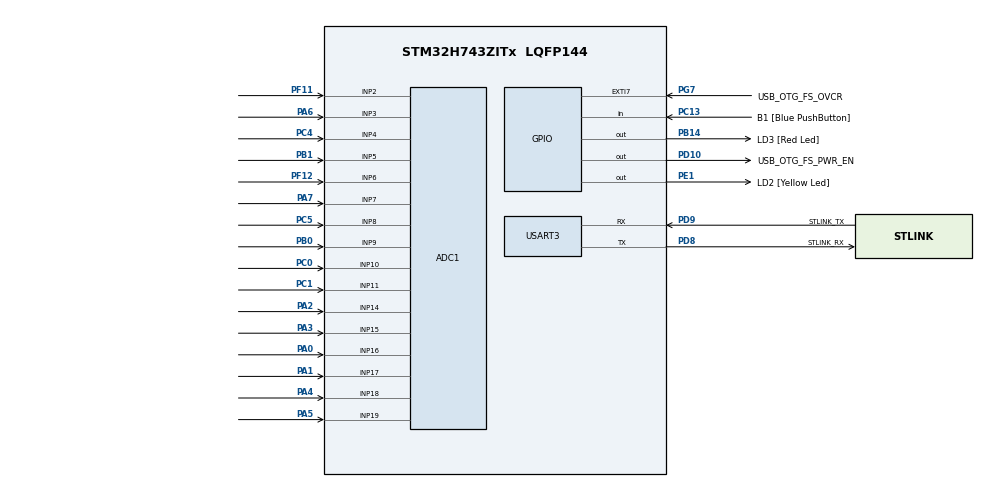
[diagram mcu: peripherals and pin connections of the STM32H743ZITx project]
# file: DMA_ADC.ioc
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ADC1.Channel-0\#ChannelRegularConversion=ADC_CHANNEL_2
ADC1.Channel-1\#ChannelRegularConversion=ADC_CHANNEL_3
ADC1.Channel-10\#ChannelRegularConversion=ADC_CHANNEL_14
ADC1.Channel-11\#ChannelRegularConversion=ADC_CHANNEL_15
ADC1.Channel-12\#ChannelRegularConversion=ADC_CHANNEL_16
ADC1.Channel-13\#ChannelRegularConversion=ADC_CHANNEL_17
ADC1.Channel-14\#ChannelRegularConversion=ADC_CHANNEL_18
ADC1.Channel-15\#ChannelRegularConversion=ADC_CHANNEL_19
ADC1.Channel-2\#ChannelRegularConversion=ADC_CHANNEL_4
ADC1.Channel-3\#ChannelRegularConversion=ADC_CHANNEL_5
ADC1.Channel-4\#ChannelRegularConversion=ADC_CHANNEL_6
ADC1.Channel-5\#ChannelRegularConversion=ADC_CHANNEL_7
ADC1.Channel-6\#ChannelRegularConversion=ADC_CHANNEL_8
ADC1.Channel-7\#ChannelRegularConversion=ADC_CHANNEL_9
ADC1.Channel-8\#ChannelRegularConversion=ADC_CHANNEL_10
ADC1.Channel-9\#ChannelRegularConversion=ADC_CHANNEL_11
ADC1.ClockPrescaler=ADC_CLOCK_ASYNC_DIV2
ADC1.ContinuousConvMode=ENABLE
ADC1.ConversionDataManagement=ADC_CONVERSIONDATA_DMA_CIRCULAR
ADC1.NbrOfConversion=16
ADC1.NbrOfConversionFlag=1
ADC1.OffsetNumber-0\#ChannelRegularConversion=ADC_OFFSET_NONE
ADC1.OffsetNumber-1\#ChannelRegularConversion=ADC_OFFSET_NONE
ADC1.OffsetNumber-10\#ChannelRegularConversion=ADC_OFFSET_NONE
ADC1.OffsetNumber-11\#ChannelRegularConversion=ADC_OFFSET_NONE
ADC1.OffsetNumber-12\#ChannelRegularConversion=ADC_OFFSET_NONE
ADC1.OffsetNumber-13\#ChannelRegularConversion=ADC_OFFSET_NONE
ADC1.OffsetNumber-14\#ChannelRegularConversion=ADC_OFFSET_NONE
ADC1.OffsetNumber-15\#ChannelRegularConversion=ADC_OFFSET_NONE
ADC1.OffsetNumber-2\#ChannelRegularConversion=ADC_OFFSET_NONE
ADC1.OffsetNumber-3\#ChannelRegularConversion=ADC_OFFSET_NONE
ADC1.OffsetNumber-4\#ChannelRegularConversion=ADC_OFFSET_NONE
ADC1.OffsetNumber-5\#ChannelRegularConversion=ADC_OFFSET_NONE
ADC1.OffsetNumber-6\#ChannelRegularConversion=ADC_OFFSET_NONE
ADC1.OffsetNumber-7\#ChannelRegularConversion=ADC_OFFSET_NONE
ADC1.OffsetNumber-8\#ChannelRegularConversion=ADC_OFFSET_NONE
ADC1.OffsetNumber-9\#ChannelRegularConversion=ADC_OFFSET_NONE
ADC1.OffsetSignedSaturation-0\#ChannelRegularConversion=DISABLE
ADC1.OffsetSignedSaturation-1\#ChannelRegularConversion=DISABLE
ADC1.OffsetSignedSaturation-10\#ChannelRegularConversion=DISABLE
ADC1.OffsetSignedSaturation-11\#ChannelRegularConversion=DISABLE
ADC1.OffsetSignedSaturation-12\#ChannelRegularConversion=DISABLE
ADC1.OffsetSignedSaturation-13\#ChannelRegularConversion=DISABLE
ADC1.OffsetSignedSaturation-14\#ChannelRegularConversion=DISABLE
ADC1.OffsetSignedSaturation-15\#ChannelRegularConversion=DISABLE
ADC1.OffsetSignedSaturation-2\#ChannelRegularConversion=DISABLE
ADC1.OffsetSignedSaturation-3\#ChannelRegularConversion=DISABLE
ADC1.OffsetSignedSaturation-4\#ChannelRegularConversion=DISABLE
ADC1.OffsetSignedSaturation-5\#ChannelRegularConversion=DISABLE
ADC1.OffsetSignedSaturation-6\#ChannelRegularConversion=DISABLE
ADC1.OffsetSignedSaturation-7\#ChannelRegularConversion=DISABLE
ADC1.OffsetSignedSaturation-8\#ChannelRegularConversion=DISABLE
ADC1.OffsetSignedSaturation-9\#ChannelRegularConversion=DISABLE
ADC1.Overrun=ADC_OVR_DATA_OVERWRITTEN
ADC1.Rank-0\#ChannelRegularConversion=1
ADC1.Rank-1\#ChannelRegularConversion=2
ADC1.Rank-10\#ChannelRegularConversion=11
ADC1.Rank-11\#ChannelRegularConversion=12
ADC1.Rank-12\#ChannelRegularConversion=13
ADC1.Rank-13\#ChannelRegularConversion=14
ADC1.Rank-14\#ChannelRegularConversion=15
ADC1.Rank-15\#ChannelRegularConversion=16
ADC1.Rank-2\#ChannelRegularConversion=3
ADC1.Rank-3\#ChannelRegularConversion=4
ADC1.Rank-4\#ChannelRegularConversion=5
ADC1.Rank-5\#ChannelRegularConversion=6
ADC1.Rank-6\#ChannelRegularConversion=7
ADC1.Rank-7\#ChannelRegularConversion=8
ADC1.Rank-8\#ChannelRegularConversion=9
ADC1.Rank-9\#ChannelRegularConversion=10
ADC1.SamplingTime-0\#ChannelRegularConversion=ADC_SAMPLETIME_1CYCLE_5
ADC1.SamplingTime-1\#ChannelRegularConversion=ADC_SAMPLETIME_1CYCLE_5
ADC1.SamplingTime-10\#ChannelRegularConversion=ADC_SAMPLETIME_1CYCLE_5
ADC1.SamplingTime-11\#ChannelRegularConversion=ADC_SAMPLETIME_1CYCLE_5
ADC1.SamplingTime-12\#ChannelRegularConversion=ADC_SAMPLETIME_1CYCLE_5
ADC1.SamplingTime-13\#ChannelRegularConversion=ADC_SAMPLETIME_1CYCLE_5
ADC1.SamplingTime-14\#ChannelRegularConversion=ADC_SAMPLETIME_1CYCLE_5
ADC1.SamplingTime-15\#ChannelRegularConversion=ADC_SAMPLETIME_1CYCLE_5
ADC1.SamplingTime-2\#ChannelRegularConversion=ADC_SAMPLETIME_1CYCLE_5
ADC1.SamplingTime-3\#ChannelRegularConversion=ADC_SAMPLETIME_1CYCLE_5
ADC1.SamplingTime-4\#ChannelRegularConversion=ADC_SAMPLETIME_1CYCLE_5
ADC1.SamplingTime-5\#ChannelRegularConversion=ADC_SAMPLETIME_1CYCLE_5
ADC1.SamplingTime-6\#ChannelRegularConversion=ADC_SAMPLETIME_1CYCLE_5
ADC1.SamplingTime-7\#ChannelRegularConversion=ADC_SAMPLETIME_1CYCLE_5
ADC1.SamplingTime-8\#ChannelRegularConversion=ADC_SAMPLETIME_1CYCLE_5
ADC1.SamplingTime-9\#ChannelRegularConversion=ADC_SAMPLETIME_1CYCLE_5
ADC1.master=1
CORTEX_M7.CPU_DCache=Disabled
Dma.ADC1.0.Direction=DMA_PERIPH_TO_MEMORY
Dma.ADC1.0.EventEnable=DISABLE
Dma.ADC1.0.FIFOMode=DMA_FIFOMODE_DISABLE
Dma.ADC1.0.Instance=DMA1_Stream0
Dma.ADC1.0.MemDataAlignment=DMA_MDATAALIGN_HALFWORD
Dma.ADC1.0.MemInc=DMA_MINC_ENABLE
Dma.ADC1.0.Mode=DMA_CIRCULAR
Dma.ADC1.0.PeriphDataAlignment=DMA_PDATAALIGN_HALFWORD
Dma.ADC1.0.PeriphInc=DMA_PINC_DISABLE
Dma.ADC1.0.Polarity=HAL_DMAMUX_REQ_GEN_RISING
Dma.ADC1.0.Priority=DMA_PRIORITY_HIGH
Dma.ADC1.0.RequestNumber=1
Dma.ADC1.0.SignalID=NONE
Dma.ADC1.0.SyncEnable=DISABLE
Dma.ADC1.0.SyncPolarity=HAL_DMAMUX_SYNC_NO_EVENT
Dma.ADC1.0.SyncRequestNumber=1
Dma.ADC1.0.SyncSignalID=NONE
Dma.Request0=ADC1
Mcu.Family=STM32H7
Mcu.Name=STM32H743ZITx
Mcu.Package=LQFP144
NVIC.DMA1_Stream0_IRQn=true\:0\:0\:false\:false\:true\:false\:true\:true
NVIC.PriorityGroup=NVIC_PRIORITYGROUP_4
NVIC.USART3_IRQn=true\:0\:0\:false\:false\:true\:true\:true\:true
PA0.Mode=IN16-Single-Ended
PA0.Signal=ADC1_INP16
PA1.Signal=SharedAnalog_PA1
PA11.Signal=USB_OTG_FS_DM
PA12.Signal=USB_OTG_FS_DP
PA13\ (JTMS/SWDIO).GPIO_Label=JTMS
PA13\ (JTMS/SWDIO).Signal=DEBUG_JTMS-SWDIO
PA14\ (JTCK/SWCLK).GPIO_Label=JTCK
PA14\ (JTCK/SWCLK).Signal=DEBUG_JTCK-SWCLK
PA2.Signal=ADCx_INP14
PA3.Signal=ADCx_INP15
PA4.Signal=ADCx_INP18
PA5.Signal=ADCx_INP19
PA6.Signal=ADCx_INP3
PA7.Signal=ADCx_INP7
PA8.Signal=USB_OTG_FS_SOF
PA9.Signal=USB_OTG_FS_VBUS
PB0.Signal=ADCx_INP9
PB1.Signal=ADCx_INP5
PB13.Signal=ETH_TXD1
PB14.GPIO_Label=LD3 [Red Led]
PB14.Signal=GPIO_Output
PC0.Signal=ADCx_INP10
PC1.Signal=ADCx_INP11
PC13.GPIO_Label=B1 [Blue PushButton]
PC13.Signal=GPIO_Input
PC14-OSC32_IN\ (OSC32_IN).Signal=RCC_OSC32_IN
PC15-OSC32_OUT\ (OSC32_OUT).Signal=RCC_OSC32_OUT
PC4.Signal=ADCx_INP4
PC5.Signal=ADCx_INP8
PD10.GPIO_Label=USB_OTG_FS_PWR_EN
PD10.Signal=GPIO_Output
PD8.GPIO_Label=STLINK_RX
PD8.Mode=Asynchronous
PD8.Signal=USART3_TX
PD9.GPIO_Label=STLINK_TX
PD9.Mode=Asynchronous
PD9.Signal=USART3_RX
PE1.GPIO_Label=LD2 [Yellow Led]
PE1.Signal=GPIO_Output
PF11.Mode=IN2-Single-Ended
PF11.Signal=ADC1_INP2
PF12.Mode=IN6-Single-Ended
PF12.Signal=ADC1_INP6
PG11.Signal=ETH_TX_EN
PG13.Signal=ETH_TXD0
PG7.GPIO_Label=USB_OTG_FS_OVCR
PG7.Signal=GPXTI7
PH0-OSC_IN\ (PH0).Signal=RCC_OSC_IN
PH1-OSC_OUT\ (PH1).Signal=RCC_OSC_OUT
ProjectManager.HeapSize=0x200
ProjectManager.StackSize=0x400
ProjectManager.TargetToolchain=STM32CubeIDE
RCC.ADCFreq_Value=37500000
RCC.APB1Freq_Value=32000000
RCC.APB2Freq_Value=64000000
RCC.APB3Freq_Value=64000000
RCC.APB4Freq_Value=64000000
RCC.CortexFreq_Value=64000000
RCC.D2PPRE1=RCC_APB1_DIV2
RCC.DIVM2=4
RCC.DIVN2=9
RCC.DIVP2=4
RCC.HCLKFreq_Value=64000000
RCC.PLL2FRACN=3072
RCC.SYSCLKFreq_VALUE=64000000
RCC.USBFreq_Value=129000000
SH.ADCx_INP10.0=ADC1_INP10,IN10-Single-Ended
SH.ADCx_INP11.0=ADC1_INP11,IN11-Single-Ended
SH.ADCx_INP14.0=ADC1_INP14,IN14-Single-Ended
SH.ADCx_INP15.0=ADC1_INP15,IN15-Single-Ended
SH.ADCx_INP18.0=ADC1_INP18,IN18-Single-Ended
SH.ADCx_INP19.0=ADC1_INP19,IN19-Single-Ended
SH.ADCx_INP3.0=ADC1_INP3,IN3-Single-Ended
SH.ADCx_INP4.0=ADC1_INP4,IN4-Single-Ended
SH.ADCx_INP5.0=ADC1_INP5,IN5-Single-Ended
SH.ADCx_INP7.0=ADC1_INP7,IN7-Single-Ended
SH.ADCx_INP8.0=ADC1_INP8,IN8-Single-Ended
SH.ADCx_INP9.0=ADC1_INP9,IN9-Single-Ended
SH.SharedAnalog_PA1.0=ADC1_INN16
SH.SharedAnalog_PA1.1=ADC1_INP17,IN17-Single-Ended
USART3.VirtualMode-Asynchronous=VM_ASYNC
board=NUCLEO-H743ZI2

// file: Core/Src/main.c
/* USER CODE BEGIN Header */
/**
  ******************************************************************************
  * @file           : main.c
  * @brief          : Main program body
  ******************************************************************************
  * @attention
  *
  * Copyright (c) 2023 STMicroelectronics.
  * All rights reserved.
  *
  * This software is licensed under terms that can be found in the LICENSE file
  * in the root directory of this software component.
  * If no LICENSE file comes with this software, it is provided AS-IS.
  *
  ******************************************************************************
  */
/* USER CODE END Header */
#include "main.h"

/* USER CODE BEGIN Includes */
#include <stdio.h>
/* USER CODE END Includes */

/* USER CODE BEGIN PD */
// Buffer Size for ADC
#define ADC_BUFFER_SIZE 64
/* USER CODE END PD */

ADC_HandleTypeDef hadc1;
DMA_HandleTypeDef hdma_adc1;

UART_HandleTypeDef huart3;

/* USER CODE BEGIN PV */

uint16_t adcResultsDMA[ADC_BUFFER_SIZE];
volatile int adcConversionComplete = 0;

char message[128];

/* USER CODE END PV */

void SystemClock_Config(void);
static void MX_GPIO_Init(void);
static void MX_DMA_Init(void);
static void MX_ADC1_Init(void);
static void MX_USART3_UART_Init(void);

int main(void)
{

  /* MCU Configuration--------------------------------------------------------*/

  /* Reset of all peripherals, Initializes the Flash interface and the Systick. */
  HAL_Init();

  /* Configure the system clock */
  SystemClock_Config();

  /* Initialize all configured peripherals */
  MX_GPIO_Init();
  MX_DMA_Init();
  MX_ADC1_Init();
  MX_USART3_UART_Init();
  /* USER CODE BEGIN 2 */

  if (HAL_ADC_Start_DMA(&hadc1, (uint16_t*)adcResultsDMA, ADC_BUFFER_SIZE) != HAL_OK) {
  		  Error_Handler();
  	  }

  /* USER CODE END 2 */

  /* Infinite loop */
  /* USER CODE BEGIN WHILE */
  while (1)
  {
	  if (adcConversionComplete == 1) {
		  sprintf(message, "%d - %d - %d\r\n", adcResultsDMA[3], adcResultsDMA[8], adcResultsDMA[11]);
		  HAL_UART_Transmit_IT(&huart3, message, sizeof(message));
		  adcConversionComplete = 0;
	  }

    /* USER CODE END WHILE */

  }
}

void SystemClock_Config(void)
{
  RCC_OscInitTypeDef RCC_OscInitStruct = {0};
  RCC_ClkInitTypeDef RCC_ClkInitStruct = {0};

  /** Supply configuration update enable
  */
  HAL_PWREx_ConfigSupply(PWR_LDO_SUPPLY);

  /** Configure the main internal regulator output voltage
  */
  __HAL_PWR_VOLTAGESCALING_CONFIG(PWR_REGULATOR_VOLTAGE_SCALE3);

  while(!__HAL_PWR_GET_FLAG(PWR_FLAG_VOSRDY)) {}

  /** Macro to configure the PLL clock source
  */
  __HAL_RCC_PLL_PLLSOURCE_CONFIG(RCC_PLLSOURCE_HSI);

  /** Initializes the RCC Oscillators according to the specified parameters
  * in the RCC_OscInitTypeDef structure.
  */
  RCC_OscInitStruct.OscillatorType = RCC_OSCILLATORTYPE_HSI;
  RCC_OscInitStruct.HSIState = RCC_HSI_DIV1;
  RCC_OscInitStruct.HSICalibrationValue = RCC_HSICALIBRATION_DEFAULT;
  RCC_OscInitStruct.PLL.PLLState = RCC_PLL_NONE;
  if (HAL_RCC_OscConfig(&RCC_OscInitStruct) != HAL_OK)
  {
    Error_Handler();
  }

  /** Initializes the CPU, AHB and APB buses clocks
  */
  RCC_ClkInitStruct.ClockType = RCC_CLOCKTYPE_HCLK|RCC_CLOCKTYPE_SYSCLK
                              |RCC_CLOCKTYPE_PCLK1|RCC_CLOCKTYPE_PCLK2
                              |RCC_CLOCKTYPE_D3PCLK1|RCC_CLOCKTYPE_D1PCLK1;
  RCC_ClkInitStruct.SYSCLKSource = RCC_SYSCLKSOURCE_HSI;
  RCC_ClkInitStruct.SYSCLKDivider = RCC_SYSCLK_DIV1;
  RCC_ClkInitStruct.AHBCLKDivider = RCC_HCLK_DIV1;
  RCC_ClkInitStruct.APB3CLKDivider = RCC_APB3_DIV1;
  RCC_ClkInitStruct.APB1CLKDivider = RCC_APB1_DIV2;
  RCC_ClkInitStruct.APB2CLKDivider = RCC_APB2_DIV1;
  RCC_ClkInitStruct.APB4CLKDivider = RCC_APB4_DIV1;

  if (HAL_RCC_ClockConfig(&RCC_ClkInitStruct, FLASH_LATENCY_1) != HAL_OK)
  {
    Error_Handler();
  }
}

static void MX_ADC1_Init(void)
{

  ADC_MultiModeTypeDef multimode = {0};
  ADC_ChannelConfTypeDef sConfig = {0};

  /** Common config
  */
  hadc1.Instance = ADC1;
  hadc1.Init.ClockPrescaler = ADC_CLOCK_ASYNC_DIV2;
  hadc1.Init.Resolution = ADC_RESOLUTION_16B;
  hadc1.Init.ScanConvMode = ADC_SCAN_ENABLE;
  hadc1.Init.EOCSelection = ADC_EOC_SINGLE_CONV;
  hadc1.Init.LowPowerAutoWait = DISABLE;
  hadc1.Init.ContinuousConvMode = ENABLE;
  hadc1.Init.NbrOfConversion = 16;
  hadc1.Init.DiscontinuousConvMode = DISABLE;
  hadc1.Init.ExternalTrigConv = ADC_SOFTWARE_START;
  hadc1.Init.ExternalTrigConvEdge = ADC_EXTERNALTRIGCONVEDGE_NONE;
  hadc1.Init.ConversionDataManagement = ADC_CONVERSIONDATA_DMA_CIRCULAR;
  hadc1.Init.Overrun = ADC_OVR_DATA_OVERWRITTEN;
  hadc1.Init.LeftBitShift = ADC_LEFTBITSHIFT_NONE;
  hadc1.Init.OversamplingMode = DISABLE;
  if (HAL_ADC_Init(&hadc1) != HAL_OK)
  {
    Error_Handler();
  }

  /** Configure the ADC multi-mode
  */
  multimode.Mode = ADC_MODE_INDEPENDENT;
  if (HAL_ADCEx_MultiModeConfigChannel(&hadc1, &multimode) != HAL_OK)
  {
    Error_Handler();
  }

  /** Configure Regular Channel
  */
  sConfig.Channel = ADC_CHANNEL_2;
  sConfig.Rank = ADC_REGULAR_RANK_1;
  sConfig.SamplingTime = ADC_SAMPLETIME_1CYCLE_5;
  sConfig.SingleDiff = ADC_SINGLE_ENDED;
  sConfig.OffsetNumber = ADC_OFFSET_NONE;
  sConfig.Offset = 0;
  sConfig.OffsetSignedSaturation = DISABLE;
  if (HAL_ADC_ConfigChannel(&hadc1, &sConfig) != HAL_OK)
  {
    Error_Handler();
  }

  /** Configure Regular Channel
  */
  sConfig.Channel = ADC_CHANNEL_3;
  sConfig.Rank = ADC_REGULAR_RANK_2;
  if (HAL_ADC_ConfigChannel(&hadc1, &sConfig) != HAL_OK)
  {
    Error_Handler();
  }

  /** Configure Regular Channel
  */
  sConfig.Channel = ADC_CHANNEL_4;
  sConfig.Rank = ADC_REGULAR_RANK_3;
  if (HAL_ADC_ConfigChannel(&hadc1, &sConfig) != HAL_OK)
  {
    Error_Handler();
  }

  /** Configure Regular Channel
  */
  sConfig.Channel = ADC_CHANNEL_5;
  sConfig.Rank = ADC_REGULAR_RANK_4;
  if (HAL_ADC_ConfigChannel(&hadc1, &sConfig) != HAL_OK)
  {
    Error_Handler();
  }

  /** Configure Regular Channel
  */
  sConfig.Channel = ADC_CHANNEL_6;
  sConfig.Rank = ADC_REGULAR_RANK_5;
  if (HAL_ADC_ConfigChannel(&hadc1, &sConfig) != HAL_OK)
  {
    Error_Handler();
  }

  /** Configure Regular Channel
  */
  sConfig.Channel = ADC_CHANNEL_7;
  sConfig.Rank = ADC_REGULAR_RANK_6;
  if (HAL_ADC_ConfigChannel(&hadc1, &sConfig) != HAL_OK)
  {
    Error_Handler();
  }

  /** Configure Regular Channel
  */
  sConfig.Channel = ADC_CHANNEL_8;
  sConfig.Rank = ADC_REGULAR_RANK_7;
  if (HAL_ADC_ConfigChannel(&hadc1, &sConfig) != HAL_OK)
  {
    Error_Handler();
  }

  /** Configure Regular Channel
  */
  sConfig.Channel = ADC_CHANNEL_9;
  sConfig.Rank = ADC_REGULAR_RANK_8;
  if (HAL_ADC_ConfigChannel(&hadc1, &sConfig) != HAL_OK)
  {
    Error_Handler();
  }

  /** Configure Regular Channel
  */
  sConfig.Channel = ADC_CHANNEL_10;
  sConfig.Rank = ADC_REGULAR_RANK_9;
  if (HAL_ADC_ConfigChannel(&hadc1, &sConfig) != HAL_OK)
  {
    Error_Handler();
  }

  /** Configure Regular Channel
  */
  sConfig.Channel = ADC_CHANNEL_11;
  sConfig.Rank = ADC_REGULAR_RANK_10;
  if (HAL_ADC_ConfigChannel(&hadc1, &sConfig) != HAL_OK)
  {
    Error_Handler();
  }

  /** Configure Regular Channel
  */
  sConfig.Channel = ADC_CHANNEL_14;
  sConfig.Rank = ADC_REGULAR_RANK_11;
  if (HAL_ADC_ConfigChannel(&hadc1, &sConfig) != HAL_OK)
  {
    Error_Handler();
  }

  /** Configure Regular Channel
  */
  sConfig.Channel = ADC_CHANNEL_15;
  sConfig.Rank = ADC_REGULAR_RANK_12;
  if (HAL_ADC_ConfigChannel(&hadc1, &sConfig) != HAL_OK)
  {
    Error_Handler();
  }

  /** Configure Regular Channel
  */
  sConfig.Channel = ADC_CHANNEL_16;
  sConfig.Rank = ADC_REGULAR_RANK_13;
  if (HAL_ADC_ConfigChannel(&hadc1, &sConfig) != HAL_OK)
  {
    Error_Handler();
  }

  /** Configure Regular Channel
  */
  sConfig.Channel = ADC_CHANNEL_17;
  sConfig.Rank = ADC_REGULAR_RANK_14;
  if (HAL_ADC_ConfigChannel(&hadc1, &sConfig) != HAL_OK)
  {
    Error_Handler();
  }

  /** Configure Regular Channel
  */
  sConfig.Channel = ADC_CHANNEL_18;
  sConfig.Rank = ADC_REGULAR_RANK_15;
  if (HAL_ADC_ConfigChannel(&hadc1, &sConfig) != HAL_OK)
  {
    Error_Handler();
  }

  /** Configure Regular Channel
  */
  sConfig.Channel = ADC_CHANNEL_19;
  sConfig.Rank = ADC_REGULAR_RANK_16;
  if (HAL_ADC_ConfigChannel(&hadc1, &sConfig) != HAL_OK)
  {
    Error_Handler();
  }

}

static void MX_USART3_UART_Init(void)
{

  huart3.Instance = USART3;
  huart3.Init.BaudRate = 115200;
  huart3.Init.WordLength = UART_WORDLENGTH_8B;
  huart3.Init.StopBits = UART_STOPBITS_1;
  huart3.Init.Parity = UART_PARITY_NONE;
  huart3.Init.Mode = UART_MODE_TX_RX;
  huart3.Init.HwFlowCtl = UART_HWCONTROL_NONE;
  huart3.Init.OverSampling = UART_OVERSAMPLING_16;
  huart3.Init.OneBitSampling = UART_ONE_BIT_SAMPLE_DISABLE;
  huart3.Init.ClockPrescaler = UART_PRESCALER_DIV1;
  huart3.AdvancedInit.AdvFeatureInit = UART_ADVFEATURE_NO_INIT;
  if (HAL_UART_Init(&huart3) != HAL_OK)
  {
    Error_Handler();
  }
  if (HAL_UARTEx_SetTxFifoThreshold(&huart3, UART_TXFIFO_THRESHOLD_1_8) != HAL_OK)
  {
    Error_Handler();
  }
  if (HAL_UARTEx_SetRxFifoThreshold(&huart3, UART_RXFIFO_THRESHOLD_1_8) != HAL_OK)
  {
    Error_Handler();
  }
  if (HAL_UARTEx_DisableFifoMode(&huart3) != HAL_OK)
  {
    Error_Handler();
  }

}

static void MX_DMA_Init(void)
{

  /* DMA controller clock enable */
  __HAL_RCC_DMA1_CLK_ENABLE();

  /* DMA interrupt init */
  /* DMA1_Stream0_IRQn interrupt configuration */
  HAL_NVIC_SetPriority(DMA1_Stream0_IRQn, 0, 0);
  HAL_NVIC_EnableIRQ(DMA1_Stream0_IRQn);

}

static void MX_GPIO_Init(void)
{
  GPIO_InitTypeDef GPIO_InitStruct = {0};

  /* GPIO Ports Clock Enable */
  __HAL_RCC_GPIOC_CLK_ENABLE();
  __HAL_RCC_GPIOH_CLK_ENABLE();
  __HAL_RCC_GPIOA_CLK_ENABLE();
  __HAL_RCC_GPIOB_CLK_ENABLE();
  __HAL_RCC_GPIOF_CLK_ENABLE();
  __HAL_RCC_GPIOD_CLK_ENABLE();
  __HAL_RCC_GPIOG_CLK_ENABLE();
  __HAL_RCC_GPIOE_CLK_ENABLE();

  /*Configure GPIO pin Output Level */
  HAL_GPIO_WritePin(LD3_GPIO_Port, LD3_Pin, GPIO_PIN_RESET);

  /*Configure GPIO pin Output Level */
  HAL_GPIO_WritePin(USB_OTG_FS_PWR_EN_GPIO_Port, USB_OTG_FS_PWR_EN_Pin, GPIO_PIN_RESET);

  /*Configure GPIO pin Output Level */
  HAL_GPIO_WritePin(LD2_GPIO_Port, LD2_Pin, GPIO_PIN_RESET);

  /*Configure GPIO pin : B1_Pin */
  GPIO_InitStruct.Pin = B1_Pin;
  GPIO_InitStruct.Mode = GPIO_MODE_INPUT;
  GPIO_InitStruct.Pull = GPIO_NOPULL;
  HAL_GPIO_Init(B1_GPIO_Port, &GPIO_InitStruct);

  /*Configure GPIO pin : PB13 */
  GPIO_InitStruct.Pin = GPIO_PIN_13;
  GPIO_InitStruct.Mode = GPIO_MODE_AF_PP;
  GPIO_InitStruct.Pull = GPIO_NOPULL;
  GPIO_InitStruct.Speed = GPIO_SPEED_FREQ_LOW;
  GPIO_InitStruct.Alternate = GPIO_AF11_ETH;
  HAL_GPIO_Init(GPIOB, &GPIO_InitStruct);

  /*Configure GPIO pin : LD3_Pin */
  GPIO_InitStruct.Pin = LD3_Pin;
  GPIO_InitStruct.Mode = GPIO_MODE_OUTPUT_PP;
  GPIO_InitStruct.Pull = GPIO_NOPULL;
  GPIO_InitStruct.Speed = GPIO_SPEED_FREQ_LOW;
  HAL_GPIO_Init(LD3_GPIO_Port, &GPIO_InitStruct);

  /*Configure GPIO pin : USB_OTG_FS_PWR_EN_Pin */
  GPIO_InitStruct.Pin = USB_OTG_FS_PWR_EN_Pin;
  GPIO_InitStruct.Mode = GPIO_MODE_OUTPUT_PP;
  GPIO_InitStruct.Pull = GPIO_NOPULL;
  GPIO_InitStruct.Speed = GPIO_SPEED_FREQ_LOW;
  HAL_GPIO_Init(USB_OTG_FS_PWR_EN_GPIO_Port, &GPIO_InitStruct);

  /*Configure GPIO pin : USB_OTG_FS_OVCR_Pin */
  GPIO_InitStruct.Pin = USB_OTG_FS_OVCR_Pin;
  GPIO_InitStruct.Mode = GPIO_MODE_IT_RISING;
  GPIO_InitStruct.Pull = GPIO_NOPULL;
  HAL_GPIO_Init(USB_OTG_FS_OVCR_GPIO_Port, &GPIO_InitStruct);

  /*Configure GPIO pins : PA8 PA11 PA12 */
  GPIO_InitStruct.Pin = GPIO_PIN_8|GPIO_PIN_11|GPIO_PIN_12;
  GPIO_InitStruct.Mode = GPIO_MODE_AF_PP;
  GPIO_InitStruct.Pull = GPIO_NOPULL;
  GPIO_InitStruct.Speed = GPIO_SPEED_FREQ_LOW;
  GPIO_InitStruct.Alternate = GPIO_AF10_OTG1_FS;
  HAL_GPIO_Init(GPIOA, &GPIO_InitStruct);

  /*Configure GPIO pins : PG11 PG13 */
  GPIO_InitStruct.Pin = GPIO_PIN_11|GPIO_PIN_13;
  GPIO_InitStruct.Mode = GPIO_MODE_AF_PP;
  GPIO_InitStruct.Pull = GPIO_NOPULL;
  GPIO_InitStruct.Speed = GPIO_SPEED_FREQ_LOW;
  GPIO_InitStruct.Alternate = GPIO_AF11_ETH;
  HAL_GPIO_Init(GPIOG, &GPIO_InitStruct);

  /*Configure GPIO pin : LD2_Pin */
  GPIO_InitStruct.Pin = LD2_Pin;
  GPIO_InitStruct.Mode = GPIO_MODE_OUTPUT_PP;
  GPIO_InitStruct.Pull = GPIO_NOPULL;
  GPIO_InitStruct.Speed = GPIO_SPEED_FREQ_LOW;
  HAL_GPIO_Init(LD2_GPIO_Port, &GPIO_InitStruct);

}

/* USER CODE BEGIN 4 */

void HAL_ADC_ConvCpltCallback(ADC_HandleTypeDef* hadc)
{
  adcConversionComplete = 1;
}

/* USER CODE END 4 */

void Error_Handler(void)
{
  __disable_irq();
  while (1)
  {
  }
}
